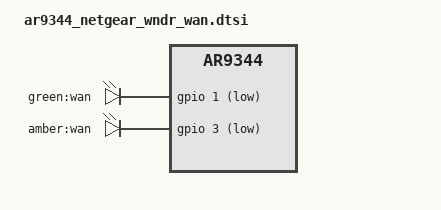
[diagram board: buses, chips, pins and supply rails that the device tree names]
// SPDX-License-Identifier: GPL-2.0-or-later OR MIT

&leds {
	wan_green {
		label = "green:wan";
		gpios = <&gpio 1 GPIO_ACTIVE_LOW>;
	};

	wan_amber {
		label = "amber:wan";
		gpios = <&gpio 3 GPIO_ACTIVE_LOW>;
	};
};
